AUTOSAR XML (schema 00046)
package /ComponentTypes
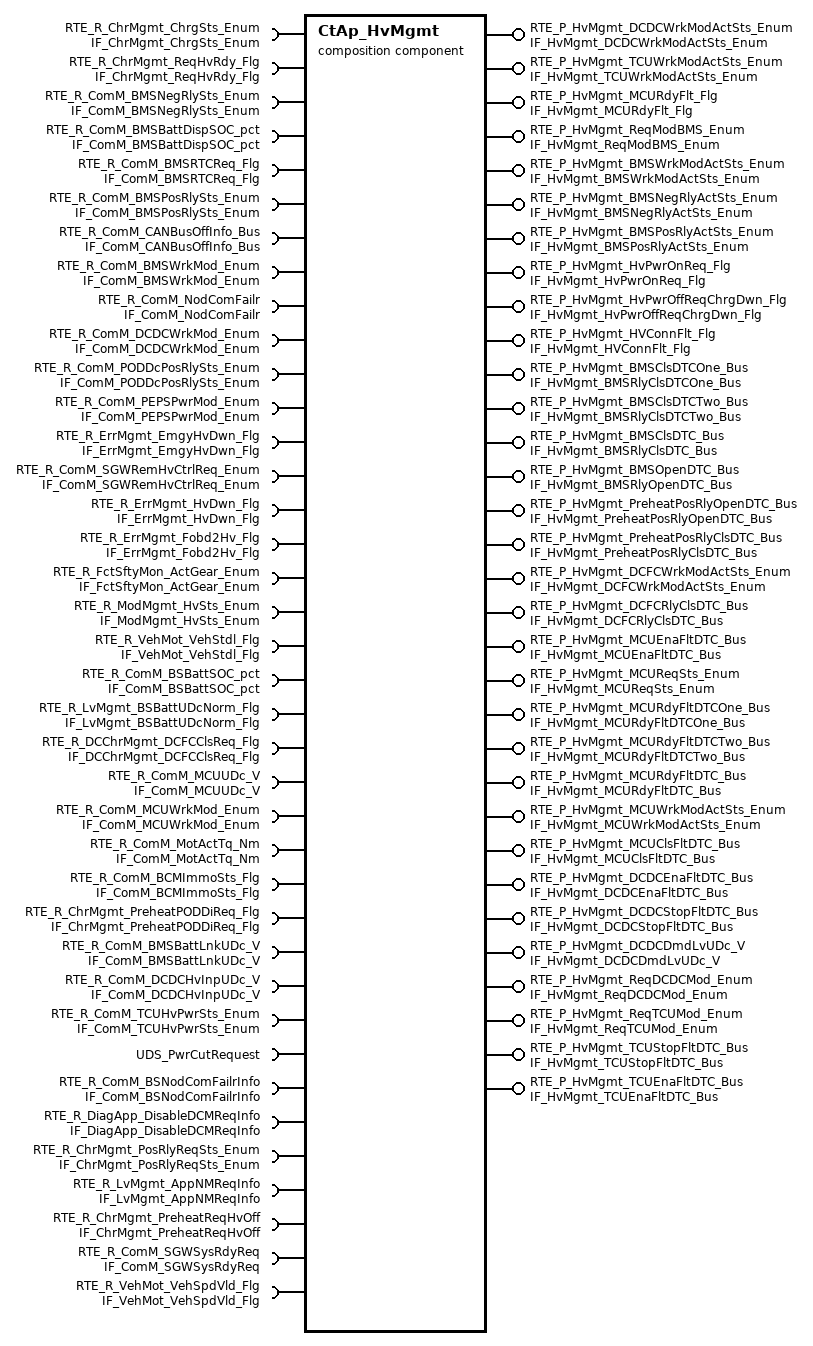
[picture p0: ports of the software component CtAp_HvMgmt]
  composition sw component type CtAp_HvMgmt
    provide port RTE_P_HvMgmt_DCDCWrkModActSts_Enum: nonqueued-sender-com-spec{data-element=tec_HvMgmt_DCDCWrkModActSts_Enum, init-value=0}, provided-interface=IF_HvMgmt_DCDCWrkModActSts_Enum
    provide port RTE_P_HvMgmt_TCUWrkModActSts_Enum: nonqueued-sender-com-spec{data-element=tec_HvMgmt_TCUWrkModActSts_Enum, init-value=0}, provided-interface=IF_HvMgmt_TCUWrkModActSts_Enum
    19 x require port:
      RTE_R_ChrMgmt_ChrgSts_Enum: nonqueued-receiver-com-spec{data-element=tec_ChrMgmt_ChrgSts_Enum, filter=data-filter-type=ALWAYS, init-value=0}, required-interface=IF_ChrMgmt_ChrgSts_Enum
      RTE_R_ChrMgmt_ReqHvRdy_Flg: nonqueued-receiver-com-spec{data-element=tec_ChrMgmt_ReqHvRdy_Flg, filter=data-filter-type=ALWAYS, init-value=0}, required-interface=IF_ChrMgmt_ReqHvRdy_Flg
      RTE_R_ComM_BMSNegRlySts_Enum: nonqueued-receiver-com-spec{data-element=tec_ComM_BMSNegRlySts_Enum, filter=data-filter-type=ALWAYS, init-value=0}, required-interface=IF_ComM_BMSNegRlySts_Enum
      RTE_R_ComM_BMSBattDispSOC_pct: nonqueued-receiver-com-spec{data-element=tec_ComM_BMSBattDispSOC_pct, filter=data-filter-type=ALWAYS, init-value=0}, required-interface=IF_ComM_BMSBattDispSOC_pct
      RTE_R_ComM_BMSRTCReq_Flg: nonqueued-receiver-com-spec{data-element=tec_ComM_BMSRTCReq_Flg, filter=data-filter-type=ALWAYS, init-value=0}, required-interface=IF_ComM_BMSRTCReq_Flg
      RTE_R_ComM_BMSPosRlySts_Enum: nonqueued-receiver-com-spec{data-element=tec_ComM_BMSPosRlySts_Enum, filter=data-filter-type=ALWAYS, init-value=0}, required-interface=IF_ComM_BMSPosRlySts_Enum
      RTE_R_ComM_CANBusOffInfo_Bus: required-interface=IF_ComM_CANBusOffInfo_Bus
        required-com-specs:
          data-element=tec_ComM_EPTCANBusOffInfo_Bus, filter=data-filter-type=ALWAYS, init-value=fields=[ComM_MonStatEPTCANBusOffInfo:0, ComM_MonResEPTCANBusOffInfo:0, ComM_ErrStatEPTCANBusOffInfo:0, ComM_ErrResEPTCANBusOffInfo:0]
          data-element=tec_ComM_CHCANBusOffInfo_Bus, filter=data-filter-type=ALWAYS, init-value=fields=[ComM_MonStatCHCANBusOffInfo:0, ComM_MonResCHCANBusOffInfo:0, ComM_ErrStatCHCANBusOffInfo:0, ComM_ErrResCHCANBusOffInfo:0]
          data-element=tec_ComM_EPTCANBusOffDTCInfo_Bus, filter=data-filter-type=ALWAYS, init-value=fields=[ComM_MonStatEPTCANBusOffDTCInfo:0, ComM_MonResEPTCANBusOffDTCInfo:0, ComM_ErrStatEPTCANBusOffDTCInfo:0, ComM_ErrResEPTCANBusOffDTCInfo:0]
          data-element=tec_ComM_CHCANBusOffDTCInfo_Bus, filter=data-filter-type=ALWAYS, init-value=fields=[ComM_MonStatCHCANBusOffDTCInfo:0, ComM_MonResCHCANBusOffDTCInfo:0, ComM_ErrStatCHCANBusOffDTCInfo:0, ComM_ErrResCHCANBusOffDTCInfo:0]
      RTE_R_ComM_BMSWrkMod_Enum: nonqueued-receiver-com-spec{data-element=tec_ComM_BMSWrkMod_Enum, filter=data-filter-type=ALWAYS, init-value=0}, required-interface=IF_ComM_BMSWrkMod_Enum
      RTE_R_ComM_NodComFailr: required-interface=IF_ComM_NodComFailr
        required-com-specs:
          data-element=tec_ComM_SGWNodComFailr_Flg, filter=data-filter-type=ALWAYS, init-value=0
          data-element=tec_ComM_CGWNodComFailr_Flg, filter=data-filter-type=ALWAYS, init-value=0
          data-element=tec_ComM_TCUNodComFailr_Flg, filter=data-filter-type=ALWAYS, init-value=0
          data-element=tec_ComM_BCMNodComFailr_Flg, filter=data-filter-type=ALWAYS, init-value=0
          data-element=tec_ComM_PRNDNodComFailr_Flg, filter=data-filter-type=ALWAYS, init-value=0
          data-element=tec_ComM_IVINodComFailr_Flg, filter=data-filter-type=ALWAYS, init-value=0
          data-element=tec_ComM_DCDCNodComFailr_Flg, filter=data-filter-type=ALWAYS, init-value=0
          data-element=tec_ComM_OBCNodComFailr_Flg, filter=data-filter-type=ALWAYS, init-value=0
          data-element=tec_ComM_CHIBSNodComFailr_Flg, filter=data-filter-type=ALWAYS, init-value=0
          data-element=tec_ComM_MCUNodComFailr_Flg, filter=data-filter-type=ALWAYS, init-value=0
          data-element=tec_ComM_EVCOMNodComFailr_Flg, filter=data-filter-type=ALWAYS, init-value=0
          data-element=tec_ComM_EPTIBSNodComFailr_Flg, filter=data-filter-type=ALWAYS, init-value=0
          data-element=tec_ComM_DCMNodComFailr_Flg, filter=data-filter-type=ALWAYS, init-value=0
          data-element=tec_ComM_BMSNodComFailr_Flg, filter=data-filter-type=ALWAYS, init-value=0
          data-element=tec_ComM_ACUNodComFailr_Flg, filter=data-filter-type=ALWAYS, init-value=0
          data-element=tec_ComM_APTCNodComFailr_Flg, filter=data-filter-type=ALWAYS, init-value=0
          data-element=tec_ComM_ADCUNodComFailr_Flg, filter=data-filter-type=ALWAYS, init-value=0
          data-element=tec_ComM_DCMRRNodComFailr_Flg, filter=data-filter-type=ALWAYS, init-value=0
          data-element=tec_ComM_DCMRLNodComFailr_Flg, filter=data-filter-type=ALWAYS, init-value=0
          data-element=tec_ComM_DCMFRNodComFailr_Flg, filter=data-filter-type=ALWAYS, init-value=0
          data-element=tec_ComM_DCMFLNodComFailr_Flg, filter=data-filter-type=ALWAYS, init-value=0
          data-element=tec_ComM_SGWCHNodComFailr_Flg, filter=data-filter-type=ALWAYS, init-value=0
      RTE_R_ComM_DCDCWrkMod_Enum: nonqueued-receiver-com-spec{data-element=tec_ComM_DCDCWrkMod_Enum, filter=data-filter-type=ALWAYS, init-value=0}, required-interface=IF_ComM_DCDCWrkMod_Enum
      RTE_R_ComM_PODDcPosRlySts_Enum: nonqueued-receiver-com-spec{data-element=tec_ComM_PODDcPosRlySts_Enum, filter=data-filter-type=ALWAYS, init-value=0}, required-interface=IF_ComM_PODDcPosRlySts_Enum
      RTE_R_ComM_PEPSPwrMod_Enum: nonqueued-receiver-com-spec{data-element=tec_ComM_PEPSPwrMod_Enum, filter=data-filter-type=ALWAYS, init-value=0}, required-interface=IF_ComM_PEPSPwrMod_Enum
      RTE_R_ErrMgmt_EmgyHvDwn_Flg: nonqueued-receiver-com-spec{data-element=tec_ErrMgmt_EmgyHvDwn_Flg, filter=data-filter-type=ALWAYS, init-value=0}, required-interface=IF_ErrMgmt_EmgyHvDwn_Flg
      RTE_R_ComM_SGWRemHvCtrlReq_Enum: nonqueued-receiver-com-spec{data-element=tec_ComM_SGWRemHvCtrlReq_Enum, filter=data-filter-type=ALWAYS, init-value=0}, required-interface=IF_ComM_SGWRemHvCtrlReq_Enum
      RTE_R_ErrMgmt_HvDwn_Flg: nonqueued-receiver-com-spec{data-element=tec_ErrMgmt_HvDwn_Flg, filter=data-filter-type=ALWAYS, init-value=0}, required-interface=IF_ErrMgmt_HvDwn_Flg
      RTE_R_ErrMgmt_Fobd2Hv_Flg: nonqueued-receiver-com-spec{data-element=tec_ErrMgmt_Fobd2Hv_Flg, filter=data-filter-type=ALWAYS, init-value=0}, required-interface=IF_ErrMgmt_Fobd2Hv_Flg
      RTE_R_FctSftyMon_ActGear_Enum: nonqueued-receiver-com-spec{data-element=tec_FctSftyMon_ActGear_Enum, filter=data-filter-type=ALWAYS, init-value=0}, required-interface=IF_FctSftyMon_ActGear_Enum
      RTE_R_ModMgmt_HvSts_Enum: nonqueued-receiver-com-spec{data-element=tec_ModMgmt_HvSts_Enum, filter=data-filter-type=ALWAYS, init-value=0}, required-interface=IF_ModMgmt_HvSts_Enum
      RTE_R_VehMot_VehStdl_Flg: nonqueued-receiver-com-spec{data-element=tec_VehMot_VehStdl_Flg, filter=data-filter-type=ALWAYS, init-value=0}, required-interface=IF_VehMot_VehStdl_Flg
    14 x provide port:
      RTE_P_HvMgmt_MCURdyFlt_Flg: nonqueued-sender-com-spec{data-element=tec_HvMgmt_MCURdyFlt_Flg, init-value=0}, provided-interface=IF_HvMgmt_MCURdyFlt_Flg
      RTE_P_HvMgmt_ReqModBMS_Enum: nonqueued-sender-com-spec{data-element=tec_HvMgmt_ReqModBMS_Enum, init-value=0}, provided-interface=IF_HvMgmt_ReqModBMS_Enum
      RTE_P_HvMgmt_BMSWrkModActSts_Enum: nonqueued-sender-com-spec{data-element=tec_HvMgmt_BMSWrkModActSts_Enum, init-value=0}, provided-interface=IF_HvMgmt_BMSWrkModActSts_Enum
      RTE_P_HvMgmt_BMSNegRlyActSts_Enum: nonqueued-sender-com-spec{data-element=tec_HvMgmt_BMSNegRlyActSts_Enum, init-value=0}, provided-interface=IF_HvMgmt_BMSNegRlyActSts_Enum
      RTE_P_HvMgmt_BMSPosRlyActSts_Enum: nonqueued-sender-com-spec{data-element=tec_HvMgmt_BMSPosRlyActSts_Enum, init-value=0}, provided-interface=IF_HvMgmt_BMSPosRlyActSts_Enum
      RTE_P_HvMgmt_HvPwrOnReq_Flg: nonqueued-sender-com-spec{data-element=tec_HvMgmt_HvPwrOnReq_Flg, init-value=0}, provided-interface=IF_HvMgmt_HvPwrOnReq_Flg
      RTE_P_HvMgmt_HvPwrOffReqChrgDwn_Flg: nonqueued-sender-com-spec{data-element=tec_HvMgmt_HvPwrOffReqChrgDwn_Flg, init-value=0}, provided-interface=IF_HvMgmt_HvPwrOffReqChrgDwn_Flg
      RTE_P_HvMgmt_HVConnFlt_Flg: nonqueued-sender-com-spec{data-element=tec_HvMgmt_HVConnFlt_Flg, init-value=0}, provided-interface=IF_HvMgmt_HVConnFlt_Flg
      RTE_P_HvMgmt_BMSClsDTCOne_Bus: nonqueued-sender-com-spec{data-element=tec_HvMgmt_BMSRlyClsDTCOne_Bus, init-value=fields=[HvMgmt_MonStatBMSRlyClsDTCOne:0, HvMgmt_MonResBMSRlyClsDTCOne:0, HvMgmt_ErrStatBMSRlyClsDTCOne:0, HvMgmt_ErrResBMSRlyClsDTCOne:0]}, provided-interface=IF_HvMgmt_BMSRlyClsDTCOne_Bus
      RTE_P_HvMgmt_BMSClsDTCTwo_Bus: nonqueued-sender-com-spec{data-element=tec_HvMgmt_BMSRlyClsDTCTwo_Bus, init-value=fields=[HvMgmt_MonStatBMSRlyClsDTCTwo:0, HvMgmt_MonResBMSRlyClsDTCTwo:0, HvMgmt_ErrStatBMSRlyClsDTCTwo:0, HvMgmt_ErrResBMSRlyClsDTCTwo:0]}, provided-interface=IF_HvMgmt_BMSRlyClsDTCTwo_Bus
      RTE_P_HvMgmt_BMSClsDTC_Bus: nonqueued-sender-com-spec{data-element=tec_HvMgmt_BMSRlyClsDTC_Bus, init-value=fields=[HvMgmt_MonStatBMSRlyClsDTC:0, HvMgmt_MonResBMSRlyClsDTC:0, HvMgmt_ErrStatBMSRlyClsDTC:0, HvMgmt_ErrResBMSRlyClsDTC:0]}, provided-interface=IF_HvMgmt_BMSRlyClsDTC_Bus
      RTE_P_HvMgmt_BMSOpenDTC_Bus: nonqueued-sender-com-spec{data-element=tec_HvMgmt_BMSRlyOpenDTC_Bus, init-value=fields=[HvMgmt_MonStatBMSRlyOpenDTC:0, HvMgmt_MonResBMSRlyOpenDTC:0, HvMgmt_ErrStatBMSRlyOpenDTC:0, HvMgmt_ErrResBMSRlyOpenDTC:0]}, provided-interface=IF_HvMgmt_BMSRlyOpenDTC_Bus
      RTE_P_HvMgmt_PreheatPosRlyOpenDTC_Bus: nonqueued-sender-com-spec{data-element=tec_HvMgmt_PreheatPosRlyOpenDTC_Bus, init-value=fields=[HvMgmt_MonStatPreheatPosRlyOpenDTC:0, HvMgmt_MonResPreheatPosRlyOpenDTC:0, HvMgmt_ErrStatPreheatPosRlyOpenDTC:0, HvMgmt_ErrResPreheatPosRlyOpenDTC:0]}, provided-interface=IF_HvMgmt_PreheatPosRlyOpenDTC_Bus
      RTE_P_HvMgmt_PreheatPosRlyClsDTC_Bus: nonqueued-sender-com-spec{data-element=tec_HvMgmt_PreheatPosRlyClsDTC_Bus, init-value=fields=[HvMgmt_MonStatPreheatPosRlyClsDTC:0, HvMgmt_MonResPreheatPosRlyClsDTC:0, HvMgmt_ErrStatPreheatPosRlyClsDTC:0, HvMgmt_ErrResPreheatPosRlyClsDTC:0]}, provided-interface=IF_HvMgmt_PreheatPosRlyClsDTC_Bus
    require port RTE_R_ComM_BSBattSOC_pct: nonqueued-receiver-com-spec{data-element=tec_ComM_BSBattSOC_pct, filter=data-filter-type=ALWAYS, init-value=0}, required-interface=IF_ComM_BSBattSOC_pct
    require port RTE_R_LvMgmt_BSBattUDcNorm_Flg: nonqueued-receiver-com-spec{data-element=tec_LvMgmt_BSBattUDcNorm_Flg, filter=data-filter-type=ALWAYS}, required-interface=IF_LvMgmt_BSBattUDcNorm_Flg
    require port RTE_R_DCChrMgmt_DCFCClsReq_Flg: nonqueued-receiver-com-spec{data-element=tec_DCChrMgmt_DCFCClsReq_Flg, filter=data-filter-type=ALWAYS, init-value=0}, required-interface=IF_DCChrMgmt_DCFCClsReq_Flg
    provide port RTE_P_HvMgmt_DCFCWrkModActSts_Enum: nonqueued-sender-com-spec{data-element=tec_HvMgmt_DCFCWrkModActSts_Enum, init-value=0}, provided-interface=IF_HvMgmt_DCFCWrkModActSts_Enum
    provide port RTE_P_HvMgmt_DCFCRlyClsDTC_Bus: nonqueued-sender-com-spec{data-element=tec_HvMgmt_DCFCRlyClsDTC_Bus, init-value=fields=[HvMgmt_MonStatDCFCRlyClsDTC:0, HvMgmt_MonResDCFCRlyClsDTC:0, HvMgmt_ErrStatDCFCRlyClsDTC:0, HvMgmt_ErrResDCFCRlyClsDTC:0]}, provided-interface=IF_HvMgmt_DCFCRlyClsDTC_Bus
    4 x require port:
      RTE_R_ComM_MCUUDc_V: nonqueued-receiver-com-spec{data-element=tec_ComM_MCUUDc_V, filter=data-filter-type=ALWAYS, init-value=0}, required-interface=IF_ComM_MCUUDc_V
      RTE_R_ComM_MCUWrkMod_Enum: nonqueued-receiver-com-spec{data-element=tec_ComM_MCUWrkMod_Enum, filter=data-filter-type=ALWAYS, init-value=0}, required-interface=IF_ComM_MCUWrkMod_Enum
      RTE_R_ComM_MotActTq_Nm: nonqueued-receiver-com-spec{data-element=tec_ComM_MotActTq_Nm, filter=data-filter-type=ALWAYS, init-value=0}, required-interface=IF_ComM_MotActTq_Nm
      RTE_R_ComM_BCMImmoSts_Flg: nonqueued-receiver-com-spec{data-element=tec_ComM_BCMImmoSts_Flg, filter=data-filter-type=ALWAYS, init-value=0}, required-interface=IF_ComM_BCMImmoSts_Flg
    7 x provide port:
      RTE_P_HvMgmt_MCUEnaFltDTC_Bus: nonqueued-sender-com-spec{data-element=tec_HvMgmt_MCUEnaFltDTC_Bus, init-value=fields=[HvMgmt_MonStatMCUEnaFltDTC:0, HvMgmt_MonResMCUEnaFltDTC:0, HvMgmt_ErrStatMCUEnaFltDTC:0, HvMgmt_ErrResMCUEnaFltDTC:0]}, provided-interface=IF_HvMgmt_MCUEnaFltDTC_Bus
      RTE_P_HvMgmt_MCUReqSts_Enum: nonqueued-sender-com-spec{data-element=tec_HvMgmt_MCUReqSts_Enum, init-value=0}, provided-interface=IF_HvMgmt_MCUReqSts_Enum
      RTE_P_HvMgmt_MCURdyFltDTCOne_Bus: nonqueued-sender-com-spec{data-element=tec_HvMgmt_MCURdyFltDTCOne_Bus, init-value=fields=[HvMgmt_MonStatMCURdyFltDTCOne:0, HvMgmt_MonResMCURdyFltDTCOne:0, HvMgmt_ErrStatMCURdyFltDTCOne:0, HvMgmt_ErrResMCURdyFltDTCOne:0]}, provided-interface=IF_HvMgmt_MCURdyFltDTCOne_Bus
      RTE_P_HvMgmt_MCURdyFltDTCTwo_Bus: nonqueued-sender-com-spec{data-element=tec_HvMgmt_MCURdyFltDTCTwo_Bus, init-value=fields=[HvMgmt_MonStatMCURdyFltDTCTwo:0, HvMgmt_MonResMCURdyFltDTCTwo:0, HvMgmt_ErrStatMCURdyFltDTCTwo:0, HvMgmt_ErrResMCURdyFltDTCTwo:0]}, provided-interface=IF_HvMgmt_MCURdyFltDTCTwo_Bus
      RTE_P_HvMgmt_MCURdyFltDTC_Bus: nonqueued-sender-com-spec{data-element=tec_HvMgmt_MCURdyFltDTC_Bus, init-value=fields=[HvMgmt_MonStatMCURdyFltDTC:0, HvMgmt_MonResMCURdyFltDTC:0, HvMgmt_ErrStatMCURdyFltDTC:0, HvMgmt_ErrResMCURdyFltDTC:0]}, provided-interface=IF_HvMgmt_MCURdyFltDTC_Bus
      RTE_P_HvMgmt_MCUWrkModActSts_Enum: nonqueued-sender-com-spec{data-element=tec_HvMgmt_MCUWrkModActSts_Enum, init-value=0}, provided-interface=IF_HvMgmt_MCUWrkModActSts_Enum
      RTE_P_HvMgmt_MCUClsFltDTC_Bus: nonqueued-sender-com-spec{data-element=tec_HvMgmt_MCUClsFltDTC_Bus, init-value=fields=[HvMgmt_MonStatMCUClsFltDTC:0, HvMgmt_MonResMCUClsFltDTC:0, HvMgmt_ErrStatMCUClsFltDTC:0, HvMgmt_ErrResMCUClsFltDTC:0]}, provided-interface=IF_HvMgmt_MCUClsFltDTC_Bus
    require port RTE_R_ChrMgmt_PreheatPODDiReq_Flg: nonqueued-receiver-com-spec{data-element=tec_ChrMgmt_PreheatPODDiReq_Flg, filter=data-filter-type=ALWAYS, init-value=0}, required-interface=IF_ChrMgmt_PreheatPODDiReq_Flg
    require port RTE_R_ComM_BMSBattLnkUDc_V: nonqueued-receiver-com-spec{data-element=tec_ComM_BMSBattLnkUDc_V, filter=data-filter-type=ALWAYS, init-value=0}, required-interface=IF_ComM_BMSBattLnkUDc_V
    require port RTE_R_ComM_DCDCHvInpUDc_V: nonqueued-receiver-com-spec{data-element=tec_ComM_DCDCHvInpUDc_V, filter=data-filter-type=ALWAYS, init-value=0}, required-interface=IF_ComM_DCDCHvInpUDc_V
    4 x provide port:
      RTE_P_HvMgmt_DCDCEnaFltDTC_Bus: nonqueued-sender-com-spec{data-element=tec_HvMgmt_DCDCEnaFltDTC_Bus, init-value=fields=[HvMgmt_MonStatDCDCEnaFltDTC:0, HvMgmt_MonResDCDCEnaFltDTC:0, HvMgmt_ErrStatDCDCEnaFltDTC:0, HvMgmt_ErrResDCDCEnaFltDTC:0]}, provided-interface=IF_HvMgmt_DCDCEnaFltDTC_Bus
      RTE_P_HvMgmt_DCDCStopFltDTC_Bus: nonqueued-sender-com-spec{data-element=tec_HvMgmt_DCDCStopFltDTC_Bus, init-value=fields=[HvMgmt_MonStatDCDCStopFltDTC:0, HvMgmt_MonResDCDCStopFltDTC:0, HvMgmt_ErrStatDCDCStopFltDTC:0, HvMgmt_ErrResDCDCStopFltDTC:0]}, provided-interface=IF_HvMgmt_DCDCStopFltDTC_Bus
      RTE_P_HvMgmt_DCDCDmdLvUDc_V: nonqueued-sender-com-spec{data-element=tec_HvMgmt_DCDCDmdLvUDc_V, init-value=0}, provided-interface=IF_HvMgmt_DCDCDmdLvUDc_V
      RTE_P_HvMgmt_ReqDCDCMod_Enum: nonqueued-sender-com-spec{data-element=tec_HvMgmt_ReqDCDCMod_Enum, init-value=0}, provided-interface=IF_HvMgmt_ReqDCDCMod_Enum
    require port RTE_R_ComM_TCUHvPwrSts_Enum: nonqueued-receiver-com-spec{data-element=tec_ComM_TCUHvPwrSts_Enum, filter=data-filter-type=ALWAYS, init-value=0}, required-interface=IF_ComM_TCUHvPwrSts_Enum
    provide port RTE_P_HvMgmt_ReqTCUMod_Enum: nonqueued-sender-com-spec{data-element=tec_HvMgmt_ReqTCUMod_Enum, init-value=0}, provided-interface=IF_HvMgmt_ReqTCUMod_Enum
    provide port RTE_P_HvMgmt_TCUStopFltDTC_Bus: nonqueued-sender-com-spec{data-element=tec_HvMgmt_TCUStopFltDTC_Bus, init-value=fields=[HvMgmt_MonStatTCUStopFltDTC:0, HvMgmt_MonResTCUStopFltDTC:0, HvMgmt_ErrStatTCUStopFltDTC:0, HvMgmt_ErrResTCUStopFltDTC:0]}, provided-interface=IF_HvMgmt_TCUStopFltDTC_Bus
    provide port RTE_P_HvMgmt_TCUEnaFltDTC_Bus: nonqueued-sender-com-spec{data-element=tec_HvMgmt_TCUEnaFltDTC_Bus, init-value=fields=[HvMgmt_MonStatTCUEnaFltDTC:0, HvMgmt_MonResTCUEnaFltDTC:0, HvMgmt_ErrStatTCUEnaFltDTC:0, HvMgmt_ErrResTCUEnaFltDTC:0]}, provided-interface=IF_HvMgmt_TCUEnaFltDTC_Bus
    8 x require port:
      UDS_PwrCutRequest: nonqueued-receiver-com-spec{data-element=PwrCutRequest, filter=data-filter-type=ALWAYS, init-value=0}, required-interface=UDS_PwrCutRequest
      RTE_R_ComM_BSNodComFailrInfo: nonqueued-receiver-com-spec{data-element=tec_ComM_BSNodComFailrInfo, filter=data-filter-type=ALWAYS, init-value=0}, required-interface=IF_ComM_BSNodComFailrInfo
      RTE_R_DiagApp_DisableDCMReqInfo: nonqueued-receiver-com-spec{data-element=tec_DiagApp_DisableDCMReqInfo, filter=data-filter-type=ALWAYS, init-value=0}, required-interface=IF_DiagApp_DisableDCMReqInfo
      RTE_R_ChrMgmt_PosRlyReqSts_Enum: nonqueued-receiver-com-spec{data-element=tec_ChrMgmt_PosRlyReqSts_Enum, filter=data-filter-type=ALWAYS, init-value=0}, required-interface=IF_ChrMgmt_PosRlyReqSts_Enum
      RTE_R_LvMgmt_AppNMReqInfo: nonqueued-receiver-com-spec{data-element=tec_LvMgmt_AppNMReqInfo, filter=data-filter-type=ALWAYS, init-value=0}, required-interface=IF_LvMgmt_AppNMReqInfo
      RTE_R_ChrMgmt_PreheatReqHvOff: nonqueued-receiver-com-spec{data-element=tec_ChrMgmt_PreheatReqHvOff, filter=data-filter-type=ALWAYS, init-value=0}, required-interface=IF_ChrMgmt_PreheatReqHvOff
      RTE_R_ComM_SGWSysRdyReq: nonqueued-receiver-com-spec{data-element=tec_ComM_SGWSysRdyReq, filter=data-filter-type=ALWAYS, init-value=0}, required-interface=IF_ComM_SGWSysRdyReq
      RTE_R_VehMot_VehSpdVld_Flg: nonqueued-receiver-com-spec{data-element=tec_VehMot_VehSpdVld_Flg, filter=data-filter-type=ALWAYS, init-value=0}, required-interface=IF_VehMot_VehSpdVld_Flg
    5 x component:
      CtAp_BMSMgmt: type=CtAp_BMSMgmt
      CtAp_DCDCMgmt: type=CtAp_DCDCMgmt
      CtAp_DCFCMgmt: type=CtAp_DCFCMgmt
      CtAp_MCUMgmt: type=CtAp_MCUMgmt
      CtAp_TCUMgmt: type=CtAp_TCUMgmt
    delegate CtAp_BMSMgmt.RTE_R_ComM_PEPSPwrMod_Enum <-> outer port RTE_R_ComM_PEPSPwrMod_Enum
    delegate CtAp_BMSMgmt.RTE_R_FctSftyMon_ActGear_Enum <-> outer port RTE_R_FctSftyMon_ActGear_Enum
    delegate CtAp_BMSMgmt.RTE_R_ErrMgmt_Fobd2Hv_Flg <-> outer port RTE_R_ErrMgmt_Fobd2Hv_Flg
    delegate CtAp_BMSMgmt.RTE_R_ErrMgmt_EmgyHvDwn_Flg <-> outer port RTE_R_ErrMgmt_EmgyHvDwn_Flg
    delegate CtAp_BMSMgmt.RTE_R_ComM_BMSRTCReq_Flg <-> outer port RTE_R_ComM_BMSRTCReq_Flg
    delegate CtAp_BMSMgmt.RTE_R_ModMgmt_HvSts_Enum <-> outer port RTE_R_ModMgmt_HvSts_Enum
    delegate CtAp_BMSMgmt.RTE_R_ComM_NodComFailr <-> outer port RTE_R_ComM_NodComFailr
    delegate CtAp_BMSMgmt.RTE_R_ChrMgmt_ChrgSts_Enum <-> outer port RTE_R_ChrMgmt_ChrgSts_Enum
    delegate CtAp_BMSMgmt.RTE_R_ComM_BMSNegRlySts_Enum <-> outer port RTE_R_ComM_BMSNegRlySts_Enum
    delegate CtAp_BMSMgmt.RTE_R_ComM_BMSPosRlySts_Enum <-> outer port RTE_R_ComM_BMSPosRlySts_Enum
    delegate CtAp_BMSMgmt.RTE_R_ComM_BMSBattDispSOC_pct <-> outer port RTE_R_ComM_BMSBattDispSOC_pct
    delegate CtAp_BMSMgmt.RTE_R_ComM_SGWRemHvCtrlReq_Enum <-> outer port RTE_R_ComM_SGWRemHvCtrlReq_Enum
    delegate CtAp_BMSMgmt.RTE_R_ErrMgmt_HvDwn_Flg <-> outer port RTE_R_ErrMgmt_HvDwn_Flg
    delegate CtAp_BMSMgmt.RTE_R_ComM_DCDCWrkMod_Enum <-> outer port RTE_R_ComM_DCDCWrkMod_Enum
    delegate CtAp_BMSMgmt.RTE_R_ComM_BMSWrkMod_Enum <-> outer port RTE_R_ComM_BMSWrkMod_Enum
    delegate CtAp_BMSMgmt.RTE_R_ComM_CANBusOffInfo_Bus <-> outer port RTE_R_ComM_CANBusOffInfo_Bus
    delegate CtAp_BMSMgmt.RTE_R_ComM_PODDcPosRlySts_Enum <-> outer port RTE_R_ComM_PODDcPosRlySts_Enum
    delegate CtAp_BMSMgmt.RTE_R_VehMot_VehStdl_Flg <-> outer port RTE_R_VehMot_VehStdl_Flg
    delegate CtAp_BMSMgmt.RTE_R_ChrMgmt_ReqHvRdy_Flg <-> outer port RTE_R_ChrMgmt_ReqHvRdy_Flg
    delegate CtAp_BMSMgmt.RTE_R_LvMgmt_BSBattUDcNorm_Flg <-> outer port RTE_R_LvMgmt_BSBattUDcNorm_Flg
    delegate CtAp_BMSMgmt.RTE_R_ComM_BSBattSOC_pct <-> outer port RTE_R_ComM_BSBattSOC_pct
    delegate CtAp_BMSMgmt.RTE_P_HvMgmt_BMSRlyClsDTC_Bus <-> outer port RTE_P_HvMgmt_BMSClsDTC_Bus
    delegate CtAp_BMSMgmt.RTE_P_HvMgmt_HvPwrOnReq_Flg <-> outer port RTE_P_HvMgmt_HvPwrOnReq_Flg
    delegate CtAp_BMSMgmt.RTE_P_HvMgmt_HvPwrOffReqChrgDwn_Flg <-> outer port RTE_P_HvMgmt_HvPwrOffReqChrgDwn_Flg
    delegate CtAp_BMSMgmt.RTE_P_HvMgmt_BMSRlyOpenDTC_Bus <-> outer port RTE_P_HvMgmt_BMSOpenDTC_Bus
    delegate CtAp_BMSMgmt.RTE_P_HvMgmt_HVConnFlt_Flg <-> outer port RTE_P_HvMgmt_HVConnFlt_Flg
    delegate CtAp_BMSMgmt.RTE_P_HvMgmt_BMSRlyClsDTCTwo_Bus <-> outer port RTE_P_HvMgmt_BMSClsDTCTwo_Bus
    delegate CtAp_BMSMgmt.RTE_P_HvMgmt_ReqModBMS_Enum <-> outer port RTE_P_HvMgmt_ReqModBMS_Enum
    delegate CtAp_BMSMgmt.RTE_P_HvMgmt_BMSRlyClsDTCOne_Bus <-> outer port RTE_P_HvMgmt_BMSClsDTCOne_Bus
    delegate CtAp_BMSMgmt.RTE_P_HvMgmt_BMSPosRlyActSts_Enum <-> outer port RTE_P_HvMgmt_BMSPosRlyActSts_Enum
    delegate CtAp_BMSMgmt.RTE_P_HvMgmt_BMSNegRlyActSts_Enum <-> outer port RTE_P_HvMgmt_BMSNegRlyActSts_Enum
    delegate CtAp_BMSMgmt.RTE_P_HvMgmt_PreheatPosRlyOpenDTC_Bus <-> outer port RTE_P_HvMgmt_PreheatPosRlyOpenDTC_Bus
    delegate CtAp_BMSMgmt.RTE_P_HvMgmt_BMSWrkModActSts_Enum <-> outer port RTE_P_HvMgmt_BMSWrkModActSts_Enum
    delegate CtAp_BMSMgmt.RTE_P_HvMgmt_PreheatPosRlyClsDTC_Bus <-> outer port RTE_P_HvMgmt_PreheatPosRlyClsDTC_Bus
    delegate CtAp_DCFCMgmt.RTE_R_ChrMgmt_ChrgSts_Enum <-> outer port RTE_R_ChrMgmt_ChrgSts_Enum
    delegate CtAp_DCFCMgmt.RTE_R_ComM_CANBusOffInfo_Bus <-> outer port RTE_R_ComM_CANBusOffInfo_Bus
    delegate CtAp_DCFCMgmt.RTE_R_ComM_BMSWrkMod_Enum <-> outer port RTE_R_ComM_BMSWrkMod_Enum
    delegate CtAp_DCFCMgmt.RTE_R_DCChrMgmt_DCFCClsReq_Flg <-> outer port RTE_R_DCChrMgmt_DCFCClsReq_Flg
    delegate CtAp_DCFCMgmt.RTE_R_ComM_PODDcPosRlySts_Enum <-> outer port RTE_R_ComM_PODDcPosRlySts_Enum
    delegate CtAp_DCFCMgmt.RTE_R_LvMgmt_BSBattUDcNorm_Flg <-> outer port RTE_R_LvMgmt_BSBattUDcNorm_Flg
    delegate CtAp_DCFCMgmt.RTE_P_HvMgmt_DCFCWrkModActSts_Enum <-> outer port RTE_P_HvMgmt_DCFCWrkModActSts_Enum
    delegate CtAp_DCFCMgmt.RTE_P_HvMgmt_DCFCRlyClsDTC_Bus <-> outer port RTE_P_HvMgmt_DCFCRlyClsDTC_Bus
    delegate CtAp_MCUMgmt.RTE_R_ComM_MCUUDc_V <-> outer port RTE_R_ComM_MCUUDc_V
    delegate CtAp_MCUMgmt.RTE_R_ComM_MCUWrkMod_Enum <-> outer port RTE_R_ComM_MCUWrkMod_Enum
    delegate CtAp_MCUMgmt.RTE_R_ComM_MotActTq_Nm <-> outer port RTE_R_ComM_MotActTq_Nm
    delegate CtAp_MCUMgmt.RTE_R_ComM_PEPSPwrMod_Enum <-> outer port RTE_R_ComM_PEPSPwrMod_Enum
    delegate CtAp_MCUMgmt.RTE_R_FctSftyMon_ActGear_Enum <-> outer port RTE_R_FctSftyMon_ActGear_Enum
    delegate CtAp_MCUMgmt.RTE_R_ComM_BCMImmoSts_Flg <-> outer port RTE_R_ComM_BCMImmoSts_Flg
    delegate CtAp_MCUMgmt.RTE_R_ChrMgmt_ChrgSts_Enum <-> outer port RTE_R_ChrMgmt_ChrgSts_Enum
    delegate CtAp_MCUMgmt.RTE_R_ComM_NodComFailr <-> outer port RTE_R_ComM_NodComFailr
    delegate CtAp_MCUMgmt.RTE_R_ErrMgmt_HvDwn_Flg <-> outer port RTE_R_ErrMgmt_HvDwn_Flg
    delegate CtAp_MCUMgmt.RTE_R_ModMgmt_HvSts_Enum <-> outer port RTE_R_ModMgmt_HvSts_Enum
    delegate CtAp_MCUMgmt.RTE_R_ComM_CANBusOffInfo_Bus <-> outer port RTE_R_ComM_CANBusOffInfo_Bus
    delegate CtAp_MCUMgmt.RTE_R_ErrMgmt_EmgyHvDwn_Flg <-> outer port RTE_R_ErrMgmt_EmgyHvDwn_Flg
    delegate CtAp_MCUMgmt.RTE_R_LvMgmt_BSBattUDcNorm_Flg <-> outer port RTE_R_LvMgmt_BSBattUDcNorm_Flg
    delegate CtAp_MCUMgmt.RTE_P_HvMgmt_MCUEnaFltDTC_Bus <-> outer port RTE_P_HvMgmt_MCUEnaFltDTC_Bus
    delegate CtAp_MCUMgmt.RTE_P_HvMgmt_MCURdyFlt_Flg <-> outer port RTE_P_HvMgmt_MCURdyFlt_Flg
    connect CtAp_MCUMgmt.RTE_P_HvMgmt_MCURdyFlt_Flg -> CtAp_BMSMgmt.RTE_R_HvMgmt_MCURdyFlt_Flg
    delegate CtAp_MCUMgmt.RTE_P_HvMgmt_MCUReqSts_Enum <-> outer port RTE_P_HvMgmt_MCUReqSts_Enum
    delegate CtAp_MCUMgmt.RTE_P_HvMgmt_MCURdyFltDTCOne_Bus <-> outer port RTE_P_HvMgmt_MCURdyFltDTCOne_Bus
    delegate CtAp_MCUMgmt.RTE_P_HvMgmt_MCURdyFltDTCTwo_Bus <-> outer port RTE_P_HvMgmt_MCURdyFltDTCTwo_Bus
    delegate CtAp_MCUMgmt.RTE_P_HvMgmt_MCURdyFltDTC_Bus <-> outer port RTE_P_HvMgmt_MCURdyFltDTC_Bus
    delegate CtAp_MCUMgmt.RTE_P_HvMgmt_MCUWrkModActSts_Enum <-> outer port RTE_P_HvMgmt_MCUWrkModActSts_Enum
    delegate CtAp_MCUMgmt.RTE_P_HvMgmt_MCUClsFltDTC_Bus <-> outer port RTE_P_HvMgmt_MCUClsFltDTC_Bus
    delegate CtAp_DCDCMgmt.RTE_R_ComM_DCDCWrkMod_Enum <-> outer port RTE_R_ComM_DCDCWrkMod_Enum
    delegate CtAp_DCDCMgmt.RTE_R_ModMgmt_HvSts_Enum <-> outer port RTE_R_ModMgmt_HvSts_Enum
    delegate CtAp_DCDCMgmt.RTE_R_ChrMgmt_PreheatPODDiReq_Flg <-> outer port RTE_R_ChrMgmt_PreheatPODDiReq_Flg
    delegate CtAp_DCDCMgmt.RTE_R_ComM_BMSBattLnkUDc_V <-> outer port RTE_R_ComM_BMSBattLnkUDc_V
    delegate CtAp_DCDCMgmt.RTE_R_ComM_CANBusOffInfo_Bus <-> outer port RTE_R_ComM_CANBusOffInfo_Bus
    delegate CtAp_DCDCMgmt.RTE_R_ComM_DCDCHvInpUDc_V <-> outer port RTE_R_ComM_DCDCHvInpUDc_V
    delegate CtAp_DCDCMgmt.RTE_R_LvMgmt_BSBattUDcNorm_Flg <-> outer port RTE_R_LvMgmt_BSBattUDcNorm_Flg
    delegate CtAp_DCDCMgmt.RTE_P_HvMgmt_DCDCEnaFltDTC_Bus <-> outer port RTE_P_HvMgmt_DCDCEnaFltDTC_Bus
    delegate CtAp_DCDCMgmt.RTE_P_HvMgmt_DCDCStopFltDTC_Bus <-> outer port RTE_P_HvMgmt_DCDCStopFltDTC_Bus
    connect CtAp_DCDCMgmt.RTE_P_HvMgmt_DCDCWrkModActSts_Enum -> CtAp_BMSMgmt.RTE_R_HvMgmt_DCDCWrkModActSts_Enum
    delegate CtAp_DCDCMgmt.RTE_P_HvMgmt_DCDCWrkModActSts_Enum <-> outer port RTE_P_HvMgmt_DCDCWrkModActSts_Enum
    delegate CtAp_DCDCMgmt.RTE_P_HvMgmt_DCDCDmdLvUDc_V <-> outer port RTE_P_HvMgmt_DCDCDmdLvUDc_V
    delegate CtAp_DCDCMgmt.RTE_P_HvMgmt_ReqDCDCMod_Enum <-> outer port RTE_P_HvMgmt_ReqDCDCMod_Enum
    connect CtAp_BMSMgmt.RTE_P_HvMgmt_ReqModBMS_Enum -> CtAp_DCDCMgmt.RTE_R_HvMgmt_ReqModBMS_Enum
    connect CtAp_BMSMgmt.RTE_P_HvMgmt_BMSWrkModActSts_Enum -> CtAp_MCUMgmt.RTE_R_HvMgmt_BMSWrkModActSts_Enum
    connect CtAp_BMSMgmt.RTE_P_HvMgmt_HvPwrOnReq_Flg -> CtAp_MCUMgmt.RTE_R_HvMgmt_HvPwrOnReq_Flg
    connect CtAp_BMSMgmt.RTE_P_HvMgmt_HvPwrOnReq_Flg -> CtAp_DCDCMgmt.RTE_R_HvMgmt_HvPwrOnReq_Flg
    delegate CtAp_TCUMgmt.RTE_R_ChrMgmt_PreheatPODDiReq_Flg <-> outer port RTE_R_ChrMgmt_PreheatPODDiReq_Flg
    delegate CtAp_TCUMgmt.RTE_R_ComM_DCDCHvInpUDc_V <-> outer port RTE_R_ComM_DCDCHvInpUDc_V
    connect CtAp_BMSMgmt.RTE_P_HvMgmt_HvPwrOnReq_Flg -> CtAp_TCUMgmt.RTE_R_HvMgmt_HvPwrOnReq_Flg
    connect CtAp_BMSMgmt.RTE_P_HvMgmt_ReqModBMS_Enum -> CtAp_TCUMgmt.RTE_R_HvMgmt_ReqModBMS_Enum
    delegate CtAp_TCUMgmt.RTE_R_ComM_BMSBattLnkUDc_V <-> outer port RTE_R_ComM_BMSBattLnkUDc_V
    delegate CtAp_TCUMgmt.RTE_R_ComM_CANBusOffInfo_Bus <-> outer port RTE_R_ComM_CANBusOffInfo_Bus
    delegate CtAp_TCUMgmt.RTE_R_ComM_TCUHvPwrSts_Enum <-> outer port RTE_R_ComM_TCUHvPwrSts_Enum
    delegate CtAp_TCUMgmt.RTE_R_ModMgmt_HvSts_Enum <-> outer port RTE_R_ModMgmt_HvSts_Enum
    delegate CtAp_TCUMgmt.RTE_R_LvMgmt_BSBattUDcNorm_Flg <-> outer port RTE_R_LvMgmt_BSBattUDcNorm_Flg
    delegate CtAp_TCUMgmt.RTE_P_HvMgmt_TCUWrkModActSts_Enum <-> outer port RTE_P_HvMgmt_TCUWrkModActSts_Enum
    delegate CtAp_TCUMgmt.RTE_P_HvMgmt_ReqTCUMod_Enum <-> outer port RTE_P_HvMgmt_ReqTCUMod_Enum
    delegate CtAp_TCUMgmt.RTE_P_HvMgmt_TCUStopFltDTC_Bus <-> outer port RTE_P_HvMgmt_TCUStopFltDTC_Bus
    delegate CtAp_TCUMgmt.RTE_P_HvMgmt_TCUEnaFltDTC_Bus <-> outer port RTE_P_HvMgmt_TCUEnaFltDTC_Bus
    connect CtAp_TCUMgmt.RTE_P_HvMgmt_TCUWrkModActSts_Enum -> CtAp_BMSMgmt.RTE_R_HvMgmt_TCUWrkModActSts_Enum
    delegate CtAp_BMSMgmt.UDS_PwrCutRequest <-> outer port UDS_PwrCutRequest
    delegate CtAp_BMSMgmt.RTE_R_ComM_BSNodComFailrInfo <-> outer port RTE_R_ComM_BSNodComFailrInfo
    delegate CtAp_BMSMgmt.RTE_R_DiagApp_DisableDCMReqInfo <-> outer port RTE_R_DiagApp_DisableDCMReqInfo
    delegate CtAp_DCFCMgmt.RTE_R_DiagApp_DisableDCMReqInfo <-> outer port RTE_R_DiagApp_DisableDCMReqInfo
    delegate CtAp_MCUMgmt.RTE_R_DiagApp_DisableDCMReqInfo <-> outer port RTE_R_DiagApp_DisableDCMReqInfo
    delegate CtAp_DCDCMgmt.RTE_R_DiagApp_DisableDCMReqInfo <-> outer port RTE_R_DiagApp_DisableDCMReqInfo
    delegate CtAp_TCUMgmt.RTE_R_DiagApp_DisableDCMReqInfo <-> outer port RTE_R_DiagApp_DisableDCMReqInfo
    delegate CtAp_BMSMgmt.RTE_R_ChrMgmt_PosRlyReqSts_Enum <-> outer port RTE_R_ChrMgmt_PosRlyReqSts_Enum
    delegate CtAp_BMSMgmt.RTE_R_LvMgmt_AppNMReqInfo <-> outer port RTE_R_LvMgmt_AppNMReqInfo
    delegate CtAp_BMSMgmt.RTE_R_ChrMgmt_PreheatReqHvOff <-> outer port RTE_R_ChrMgmt_PreheatReqHvOff
    delegate CtAp_MCUMgmt.RTE_R_ComM_SGWSysRdyReq <-> outer port RTE_R_ComM_SGWSysRdyReq
    delegate CtAp_BMSMgmt.RTE_R_VehMot_VehSpdVld_Flg <-> outer port RTE_R_VehMot_VehSpdVld_Flg
